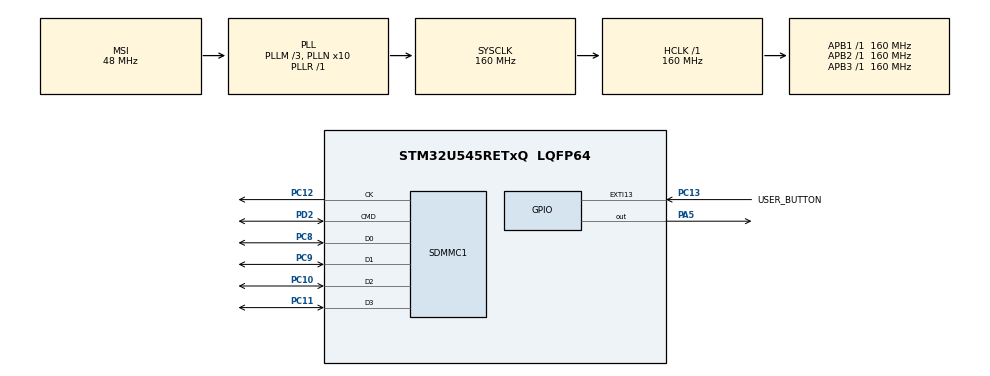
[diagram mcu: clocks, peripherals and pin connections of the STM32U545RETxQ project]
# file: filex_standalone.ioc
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CORTEX_M33_NS.userName=CORTEX_M33
FILEX.FX_SD_INTERFACE=1
Mcu.Family=STM32U5
Mcu.Name=STM32U545RETxQ
Mcu.Package=LQFP64
NUCLEO-U545RE-Q.LD2=true
NUCLEO-U545RE-Q.VCP=true
NVIC.PriorityGroup=NVIC_PRIORITYGROUP_4
NVIC.SDMMC1_IRQn=true\:0\:0\:false\:false\:true\:true\:true\:true
PA5.Signal=GPIO_Output
PC10.GPIO_PuPd=GPIO_PULLUP
PC10.Mode=SD_4_bits_Wide_bus
PC10.Signal=SDMMC1_D2
PC11.GPIO_PuPd=GPIO_PULLUP
PC11.Mode=SD_4_bits_Wide_bus
PC11.Signal=SDMMC1_D3
PC12.Mode=SD_4_bits_Wide_bus
PC12.Signal=SDMMC1_CK
PC13.GPIO_Label=USER_BUTTON
PC13.GPIO_ModeDefaultEXTI=GPIO_MODE_IT_FALLING
PC13.GPIO_PuPd=GPIO_PULLDOWN
PC13.Signal=GPXTI13
PC8.GPIO_PuPd=GPIO_PULLUP
PC8.Mode=SD_4_bits_Wide_bus
PC8.Signal=SDMMC1_D0
PC9.GPIO_PuPd=GPIO_PULLUP
PC9.Mode=SD_4_bits_Wide_bus
PC9.Signal=SDMMC1_D1
PD2.GPIO_PuPd=GPIO_PULLUP
PD2.Mode=SD_4_bits_Wide_bus
PD2.Signal=SDMMC1_CMD
PWR.PowerMode=PWR_SMPS_SUPPLY
ProjectManager.HeapSize=0x200
ProjectManager.StackSize=0x400
ProjectManager.TargetToolchain=STM32CubeIDE
RCC.ADCFreq_Value=16000000
RCC.AHBFreq_Value=160000000
RCC.APB1Freq_Value=160000000
RCC.APB1TimFreq_Value=160000000
RCC.APB2Freq_Value=160000000
RCC.APB2TimFreq_Value=160000000
RCC.APB3Freq_Value=160000000
RCC.CortexFreq_Value=160000000
RCC.DACCLockSelectionVirtual=RCC_DAC1CLKSOURCE_LSI
RCC.DACCLockSelectionVirtualString=RCC_DAC1CLKSOURCE_LSI
RCC.EPOD_VALUE=48000000
RCC.HCLKFreq_Value=160000000
RCC.HSE_VALUE=16000000
RCC.HSI48_VALUE=48000000
RCC.HSI_VALUE=16000000
RCC.LSE_VALUE=32768
RCC.LSIDIV_VALUE=32000
RCC.MSIClockRange=RCC_MSIRANGE_0
RCC.MSI_VALUE=48000000
RCC.PLL1P=4
RCC.PLL1R=1
RCC.PLL2FRACN=0
RCC.PLL3FRACN=0
RCC.PLLFRACN=0
RCC.PLLM=3
RCC.PLLN=10
RCC.SDMMCClockSelection=RCC_SDMMCCLKSOURCE_CLK48
RCC.SYSCLKFreq_VALUE=160000000
RCC.SYSCLKSource=RCC_SYSCLKSOURCE_PLLCLK
RCC.USBFreq_Value=48000000
RCC.VCOOutputFreq_Value=160000000
SDMMC1.ClockDiv=2
VP_FILEX_VS_FileOoSystemJjFileXJjCore.Mode=FileX_Core
VP_FILEX_VS_SDOointerface.Mode=SD_interface
VP_ICACHE_VS_ICACHE.Mode=DirectMappedCache
VP_LPBAMQUEUE_VS_QUEUE.Mode=QUEUEMODE
VP_LPBAM_VS_SIG1.Mode=SmartRun
VP_LPBAM_VS_SIG4.Mode=LPDMA1
VP_MEMORYMAP_VS_MEMORYMAP.Mode=CurAppReg
VP_NUCLEO-U545RE-Q_VS_BSP_COMMON.Mode=COMMON
VP_PWR_VS_LPOM.Mode=PowerOptimisation
VP_PWR_VS_SECSignals.Mode=Security/Privilege
board=NUCLEO-U545RE-Q

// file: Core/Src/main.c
/* USER CODE BEGIN Header */
/**
  ******************************************************************************
  * @file           : main.c
  * @brief          : Main program body
  ******************************************************************************
  * @attention
  *
  * Copyright (c) 2025 STMicroelectronics.
  * All rights reserved.
  *
  * This software is licensed under terms that can be found in the LICENSE file
  * in the root directory of this software component.
  * If no LICENSE file comes with this software, it is provided AS-IS.
  *
  ******************************************************************************
  */
/* USER CODE END Header */
#include "main.h"
#include "app_filex.h"

COM_InitTypeDef BspCOMInit;

SD_HandleTypeDef hsd1;

void SystemClock_Config(void);
static void SystemPower_Config(void);
static void MX_GPIO_Init(void);
static void MX_ICACHE_Init(void);
static void MX_SDMMC1_SD_Init(void);

int main(void)
{

  /* MCU Configuration--------------------------------------------------------*/

  /* Reset of all peripherals, Initializes the Flash interface and the Systick. */
  HAL_Init();

  /* Configure the System Power */
  SystemPower_Config();

  /* Configure the system clock */
  SystemClock_Config();

  /* Initialize all configured peripherals */
  MX_GPIO_Init();
  MX_ICACHE_Init();
  MX_SDMMC1_SD_Init();
  MX_FileX_Init();
  /* USER CODE BEGIN 2 */
  MX_FileX_Process();
  /* USER CODE END 2 */

  /* Initialize led */
  BSP_LED_Init(LED_GREEN);

  /* Initialize COM1 port (115200, 8 bits (7-bit data + 1 stop bit), no parity */
  BspCOMInit.BaudRate   = 115200;
  BspCOMInit.WordLength = COM_WORDLENGTH_8B;
  BspCOMInit.StopBits   = COM_STOPBITS_1;
  BspCOMInit.Parity     = COM_PARITY_NONE;
  BspCOMInit.HwFlowCtl  = COM_HWCONTROL_NONE;
  if (BSP_COM_Init(COM1, &BspCOMInit) != BSP_ERROR_NONE)
  {
    Error_Handler();
  }

  /* Infinite loop */
  while (1)
  {

  }
}

void SystemClock_Config(void)
{
  RCC_OscInitTypeDef RCC_OscInitStruct = {0};
  RCC_ClkInitTypeDef RCC_ClkInitStruct = {0};

  /** Configure the main internal regulator output voltage
  */
  if (HAL_PWREx_ControlVoltageScaling(PWR_REGULATOR_VOLTAGE_SCALE1) != HAL_OK)
  {
    Error_Handler();
  }

  /** Initializes the CPU, AHB and APB buses clocks
  */
  RCC_OscInitStruct.OscillatorType = RCC_OSCILLATORTYPE_HSI48|RCC_OSCILLATORTYPE_MSI;
  RCC_OscInitStruct.HSI48State = RCC_HSI48_ON;
  RCC_OscInitStruct.MSIState = RCC_MSI_ON;
  RCC_OscInitStruct.MSICalibrationValue = RCC_MSICALIBRATION_DEFAULT;
  RCC_OscInitStruct.MSIClockRange = RCC_MSIRANGE_0;
  RCC_OscInitStruct.PLL.PLLState = RCC_PLL_ON;
  RCC_OscInitStruct.PLL.PLLSource = RCC_PLLSOURCE_MSI;
  RCC_OscInitStruct.PLL.PLLMBOOST = RCC_PLLMBOOST_DIV4;
  RCC_OscInitStruct.PLL.PLLM = 3;
  RCC_OscInitStruct.PLL.PLLN = 10;
  RCC_OscInitStruct.PLL.PLLP = 4;
  RCC_OscInitStruct.PLL.PLLQ = 2;
  RCC_OscInitStruct.PLL.PLLR = 1;
  RCC_OscInitStruct.PLL.PLLRGE = RCC_PLLVCIRANGE_1;
  RCC_OscInitStruct.PLL.PLLFRACN = 0;
  if (HAL_RCC_OscConfig(&RCC_OscInitStruct) != HAL_OK)
  {
    Error_Handler();
  }

  /** Initializes the CPU, AHB and APB buses clocks
  */
  RCC_ClkInitStruct.ClockType = RCC_CLOCKTYPE_HCLK|RCC_CLOCKTYPE_SYSCLK
                              |RCC_CLOCKTYPE_PCLK1|RCC_CLOCKTYPE_PCLK2
                              |RCC_CLOCKTYPE_PCLK3;
  RCC_ClkInitStruct.SYSCLKSource = RCC_SYSCLKSOURCE_PLLCLK;
  RCC_ClkInitStruct.AHBCLKDivider = RCC_SYSCLK_DIV1;
  RCC_ClkInitStruct.APB1CLKDivider = RCC_HCLK_DIV1;
  RCC_ClkInitStruct.APB2CLKDivider = RCC_HCLK_DIV1;
  RCC_ClkInitStruct.APB3CLKDivider = RCC_HCLK_DIV1;

  if (HAL_RCC_ClockConfig(&RCC_ClkInitStruct, FLASH_LATENCY_4) != HAL_OK)
  {
    Error_Handler();
  }
}

/**
  * @brief Power Configuration
  * @retval None
  */
static void SystemPower_Config(void)
{

  /*
   * Switch to SMPS regulator instead of LDO
   */
  if (HAL_PWREx_ConfigSupply(PWR_SMPS_SUPPLY) != HAL_OK)
  {
    Error_Handler();
  }
}

static void MX_ICACHE_Init(void)
{

  /** Enable instruction cache in 1-way (direct mapped cache)
  */
  if (HAL_ICACHE_ConfigAssociativityMode(ICACHE_1WAY) != HAL_OK)
  {
    Error_Handler();
  }
  if (HAL_ICACHE_Enable() != HAL_OK)
  {
    Error_Handler();
  }

}

static void MX_SDMMC1_SD_Init(void)
{

  hsd1.Instance = SDMMC1;
  hsd1.Init.ClockEdge = SDMMC_CLOCK_EDGE_RISING;
  hsd1.Init.ClockPowerSave = SDMMC_CLOCK_POWER_SAVE_DISABLE;
  hsd1.Init.BusWide = SDMMC_BUS_WIDE_4B;
  hsd1.Init.HardwareFlowControl = SDMMC_HARDWARE_FLOW_CONTROL_DISABLE;
  hsd1.Init.ClockDiv = 2;
  if (HAL_SD_Init(&hsd1) != HAL_OK)
  {
    Error_Handler();
  }

}

static void MX_GPIO_Init(void)
{
  GPIO_InitTypeDef GPIO_InitStruct = {0};

  /* GPIO Ports Clock Enable */
  __HAL_RCC_GPIOC_CLK_ENABLE();
  __HAL_RCC_GPIOD_CLK_ENABLE();

  /*Configure GPIO pin : USER_BUTTON_Pin */
  GPIO_InitStruct.Pin = USER_BUTTON_Pin;
  GPIO_InitStruct.Mode = GPIO_MODE_IT_FALLING;
  GPIO_InitStruct.Pull = GPIO_PULLDOWN;
  HAL_GPIO_Init(USER_BUTTON_GPIO_Port, &GPIO_InitStruct);

}

void Error_Handler(void)
{
  __disable_irq();
  while (1)
  {
  }
}
